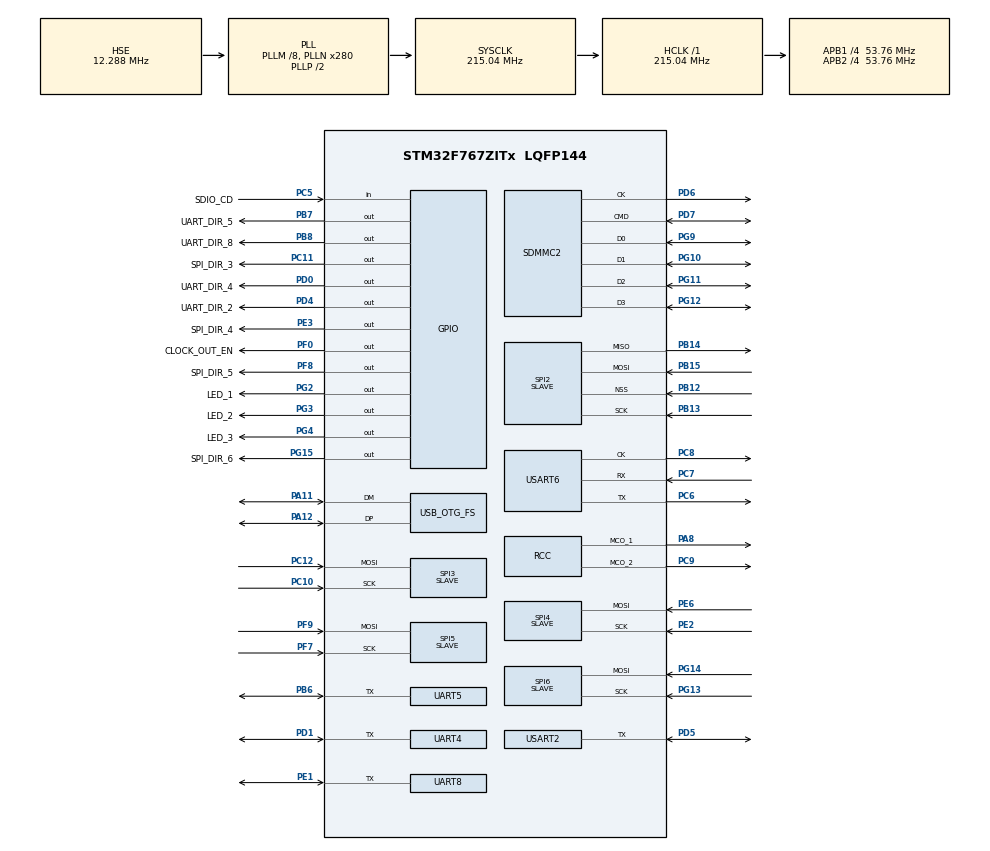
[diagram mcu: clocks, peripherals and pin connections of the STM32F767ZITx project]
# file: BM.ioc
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Dma.Request0=SPI3_RX
Dma.Request1=SPI4_RX
Dma.Request2=SPI5_RX
Dma.Request3=SPI6_RX
Dma.SPI3_RX.0.Direction=DMA_PERIPH_TO_MEMORY
Dma.SPI3_RX.0.FIFOMode=DMA_FIFOMODE_DISABLE
Dma.SPI3_RX.0.Instance=DMA1_Stream0
Dma.SPI3_RX.0.MemDataAlignment=DMA_MDATAALIGN_HALFWORD
Dma.SPI3_RX.0.MemInc=DMA_MINC_ENABLE
Dma.SPI3_RX.0.Mode=DMA_CIRCULAR
Dma.SPI3_RX.0.PeriphDataAlignment=DMA_PDATAALIGN_HALFWORD
Dma.SPI3_RX.0.PeriphInc=DMA_PINC_DISABLE
Dma.SPI3_RX.0.Priority=DMA_PRIORITY_MEDIUM
Dma.SPI4_RX.1.Direction=DMA_PERIPH_TO_MEMORY
Dma.SPI4_RX.1.FIFOMode=DMA_FIFOMODE_DISABLE
Dma.SPI4_RX.1.Instance=DMA2_Stream0
Dma.SPI4_RX.1.MemDataAlignment=DMA_MDATAALIGN_HALFWORD
Dma.SPI4_RX.1.MemInc=DMA_MINC_ENABLE
Dma.SPI4_RX.1.Mode=DMA_CIRCULAR
Dma.SPI4_RX.1.PeriphDataAlignment=DMA_PDATAALIGN_HALFWORD
Dma.SPI4_RX.1.PeriphInc=DMA_PINC_DISABLE
Dma.SPI4_RX.1.Priority=DMA_PRIORITY_MEDIUM
Dma.SPI5_RX.2.Direction=DMA_PERIPH_TO_MEMORY
Dma.SPI5_RX.2.FIFOMode=DMA_FIFOMODE_DISABLE
Dma.SPI5_RX.2.Instance=DMA2_Stream3
Dma.SPI5_RX.2.MemDataAlignment=DMA_MDATAALIGN_BYTE
Dma.SPI5_RX.2.MemInc=DMA_MINC_ENABLE
Dma.SPI5_RX.2.Mode=DMA_CIRCULAR
Dma.SPI5_RX.2.PeriphDataAlignment=DMA_PDATAALIGN_BYTE
Dma.SPI5_RX.2.PeriphInc=DMA_PINC_DISABLE
Dma.SPI5_RX.2.Priority=DMA_PRIORITY_MEDIUM
Dma.SPI6_RX.3.Direction=DMA_PERIPH_TO_MEMORY
Dma.SPI6_RX.3.FIFOMode=DMA_FIFOMODE_DISABLE
Dma.SPI6_RX.3.Instance=DMA2_Stream6
Dma.SPI6_RX.3.MemDataAlignment=DMA_MDATAALIGN_BYTE
Dma.SPI6_RX.3.MemInc=DMA_MINC_ENABLE
Dma.SPI6_RX.3.Mode=DMA_CIRCULAR
Dma.SPI6_RX.3.PeriphDataAlignment=DMA_PDATAALIGN_BYTE
Dma.SPI6_RX.3.PeriphInc=DMA_PINC_DISABLE
Dma.SPI6_RX.3.Priority=DMA_PRIORITY_MEDIUM
Mcu.Family=STM32F7
Mcu.Name=STM32F767ZITx
Mcu.Package=LQFP144
NVIC.DMA1_Stream0_IRQn=true\:0\:0\:false\:false\:true\:false
NVIC.DMA2_Stream0_IRQn=true\:0\:0\:false\:false\:true\:false
NVIC.DMA2_Stream3_IRQn=true\:0\:0\:false\:false\:true\:false
NVIC.DMA2_Stream6_IRQn=true\:0\:0\:false\:false\:true\:false
NVIC.OTG_FS_IRQn=true\:0\:0\:false\:false\:true\:false
NVIC.PriorityGroup=NVIC_PRIORITYGROUP_4
NVIC.TIM1_UP_TIM10_IRQn=true\:0\:0\:false\:false\:true\:true
PA11.Mode=Device_Only
PA11.Signal=USB_OTG_FS_DM
PA12.Mode=Device_Only
PA12.Signal=USB_OTG_FS_DP
PA8.Mode=Clock-out-1
PA8.Signal=RCC_MCO_1
PB12.Mode=NSS_Signal_Hard_Input
PB12.Signal=SPI2_NSS
PB13.Mode=Full_Duplex_Slave
PB13.Signal=SPI2_SCK
PB14.Mode=Full_Duplex_Slave
PB14.Signal=SPI2_MISO
PB15.Mode=Full_Duplex_Slave
PB15.Signal=SPI2_MOSI
PB6.Mode=Half_duplex(single_wire_mode)
PB6.Signal=UART5_TX
PB7.GPIO_Label=UART_DIR_5
PB7.GPIO_Speed=GPIO_SPEED_FREQ_VERY_HIGH
PB7.Signal=GPIO_Output
PB8.GPIO_Label=UART_DIR_8
PB8.GPIO_Speed=GPIO_SPEED_FREQ_VERY_HIGH
PB8.Signal=GPIO_Output
PC10.Mode=RX_Only_Simplex_Unidirect_Slave
PC10.Signal=SPI3_SCK
PC11.GPIO_Label=SPI_DIR_3
PC11.GPIO_Speed=GPIO_SPEED_FREQ_VERY_HIGH
PC11.Signal=GPIO_Output
PC12.Mode=RX_Only_Simplex_Unidirect_Slave
PC12.Signal=SPI3_MOSI
PC14/OSC32_IN.Mode=LSE-External-Oscillator
PC14/OSC32_IN.Signal=RCC_OSC32_IN
PC15/OSC32_OUT.Mode=LSE-External-Oscillator
PC15/OSC32_OUT.Signal=RCC_OSC32_OUT
PC5.GPIO_Label=SDIO_CD
PC5.Signal=GPIO_Input
PC6.Mode=Synchronous
PC6.Signal=USART6_TX
PC7.Mode=Synchronous
PC7.Signal=USART6_RX
PC8.Mode=Synchronous
PC8.Signal=USART6_CK
PC9.Mode=Clock-out-2
PC9.Signal=RCC_MCO_2
PD0.GPIO_Label=UART_DIR_4
PD0.GPIO_Speed=GPIO_SPEED_FREQ_VERY_HIGH
PD0.Signal=GPIO_Output
PD1.Mode=Half_duplex(single_wire_mode)
PD1.Signal=UART4_TX
PD4.GPIO_Label=UART_DIR_2
PD4.GPIO_Speed=GPIO_SPEED_FREQ_VERY_HIGH
PD4.Signal=GPIO_Output
PD5.Mode=Half_duplex(single_wire_mode)
PD5.Signal=USART2_TX
PD6.Mode=SD_4_bits_Wide_bus
PD6.Signal=SDMMC2_CK
PD7.Mode=SD_4_bits_Wide_bus
PD7.Signal=SDMMC2_CMD
PE1.Mode=Half_duplex(single_wire_mode)
PE1.Signal=UART8_TX
PE2.Mode=RX_Only_Simplex_Unidirect_Slave
PE2.Signal=SPI4_SCK
PE3.GPIO_Label=SPI_DIR_4
PE3.GPIO_Speed=GPIO_SPEED_FREQ_VERY_HIGH
PE3.Signal=GPIO_Output
PE6.Mode=RX_Only_Simplex_Unidirect_Slave
PE6.Signal=SPI4_MOSI
PF0.GPIO_Label=CLOCK_OUT_EN
PF0.GPIO_Speed=GPIO_SPEED_FREQ_VERY_HIGH
PF0.Signal=GPIO_Output
PF7.Mode=RX_Only_Simplex_Unidirect_Slave
PF7.Signal=SPI5_SCK
PF8.GPIO_Label=SPI_DIR_5
PF8.GPIO_Speed=GPIO_SPEED_FREQ_VERY_HIGH
PF8.Signal=GPIO_Output
PF9.Mode=RX_Only_Simplex_Unidirect_Slave
PF9.Signal=SPI5_MOSI
PG10.Mode=SD_4_bits_Wide_bus
PG10.Signal=SDMMC2_D1
PG11.Mode=SD_4_bits_Wide_bus
PG11.Signal=SDMMC2_D2
PG12.Mode=SD_4_bits_Wide_bus
PG12.Signal=SDMMC2_D3
PG13.Mode=RX_Only_Simplex_Unidirect_Slave
PG13.Signal=SPI6_SCK
PG14.Mode=RX_Only_Simplex_Unidirect_Slave
PG14.Signal=SPI6_MOSI
PG15.GPIO_Label=SPI_DIR_6
PG15.GPIO_Speed=GPIO_SPEED_FREQ_VERY_HIGH
PG15.Signal=GPIO_Output
PG2.GPIO_Label=LED_1
PG2.GPIO_Speed=GPIO_SPEED_FREQ_VERY_HIGH
PG2.Signal=GPIO_Output
PG3.GPIO_Label=LED_2
PG3.GPIO_Speed=GPIO_SPEED_FREQ_VERY_HIGH
PG3.Signal=GPIO_Output
PG4.GPIO_Label=LED_3
PG4.GPIO_Speed=GPIO_SPEED_FREQ_VERY_HIGH
PG4.Signal=GPIO_Output
PG9.Mode=SD_4_bits_Wide_bus
PG9.Signal=SDMMC2_D0
PH0/OSC_IN.Mode=HSE-External-Oscillator
PH0/OSC_IN.Signal=RCC_OSC_IN
PH1/OSC_OUT.Mode=HSE-External-Oscillator
PH1/OSC_OUT.Signal=RCC_OSC_OUT
ProjectManager.HeapSize=0x200
ProjectManager.StackSize=0x400
ProjectManager.TargetToolchain=MDK-ARM V5
RCC.AHBFreq_Value=215040000
RCC.APB1CLKDivider=RCC_HCLK_DIV4
RCC.APB1Freq_Value=53760000
RCC.APB1TimFreq_Value=107520000
RCC.APB2CLKDivider=RCC_HCLK_DIV4
RCC.APB2Freq_Value=53760000
RCC.APB2TimFreq_Value=107520000
RCC.CortexFreq_Value=215040000
RCC.HCLKFreq_Value=215040000
RCC.HSE_VALUE=12288000
RCC.HSI_VALUE=16000000
RCC.PLL48CLockSelection=RCC_CLK48SOURCE_PLLSAIP
RCC.PLLI2SN=224
RCC.PLLI2SR=7
RCC.PLLM=8
RCC.PLLN=280
RCC.PLLQ=8
RCC.PLLSAIN=250
RCC.PLLSAIP=RCC_PLLSAIP_DIV8
RCC.RCC_MCO1Source=RCC_MCO1SOURCE_HSE
RCC.RCC_MCO2Source=RCC_MCO2SOURCE_PLLI2SCLK
RCC.SDMMC2ClockSelection=RCC_SDMMC2CLKSOURCE_CLK48
RCC.SYSCLKFreq_VALUE=215040000
RCC.SYSCLKSource=RCC_SYSCLKSOURCE_PLLCLK
RCC.USBFreq_Value=48000000
RCC.VCOOutputFreq_Value=430080000
SPI2.Direction=SPI_DIRECTION_2LINES
SPI2.Mode=SPI_MODE_SLAVE
SPI2.VirtualNSS=VM_NSSHARD
SPI2.VirtualType=VM_SLAVE
SPI3.DataSize=SPI_DATASIZE_16BIT
SPI3.Direction=SPI_DIRECTION_2LINES_RXONLY
SPI3.Mode=SPI_MODE_SLAVE
SPI3.VirtualType=VM_SLAVE
SPI4.DataSize=SPI_DATASIZE_16BIT
SPI4.Direction=SPI_DIRECTION_2LINES_RXONLY
SPI4.Mode=SPI_MODE_SLAVE
SPI4.VirtualType=VM_SLAVE
SPI5.Direction=SPI_DIRECTION_2LINES_RXONLY
SPI5.Mode=SPI_MODE_SLAVE
SPI5.VirtualType=VM_SLAVE
SPI6.Direction=SPI_DIRECTION_2LINES_RXONLY
SPI6.Mode=SPI_MODE_SLAVE
SPI6.VirtualType=VM_SLAVE
TIM1.Period=10000
TIM1.Prescaler=10700
USART2.VirtualMode-Half_duplex(single_wire_mode)=VM_ASYNC
USART6.VirtualMode-Synchronous=VM_SYNC
USB_DEVICE.CLASS_NAME_FS=CDC
USB_DEVICE.USBD_LPM_ENABLED-CDC_FS=0
USB_DEVICE.USBD_SUPPORT_USER_STRING-CDC_FS=1
USB_DEVICE.VirtualMode-CDC_FS=Cdc
USB_DEVICE.VirtualModeFS=Cdc_FS
USB_OTG_FS.VirtualMode=Device_Only
USB_OTG_FS.lpm_enable=DISABLE
VP_FATFS_VS_SDIO.Mode=SDIO
VP_TIM1_VS_ClockSourceINT.Mode=Internal
VP_USB_DEVICE_VS_USB_DEVICE_CDC_FS.Mode=CDC_FS
board=BM

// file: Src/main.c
/**
  ******************************************************************************
  * @file           : main.c
  * @brief          : Main program body
  ******************************************************************************
  * This notice applies to any and all portions of this file
  * that are not between comment pairs USER CODE BEGIN and
  * USER CODE END. Other portions of this file, whether
  * inserted by the user or by software development tools
  * are owned by their respective copyright owners.
  *
  * Copyright (c) 2018 STMicroelectronics International N.V.
  * All rights reserved.
  *
  * Redistribution and use in source and binary forms, with or without
  * modification, are permitted, provided that the following conditions are met:
  *
  * 1. Redistribution of source code must retain the above copyright notice,
  *    this list of conditions and the following disclaimer.
  * 2. Redistributions in binary form must reproduce the above copyright notice,
  *    this list of conditions and the following disclaimer in the documentation
  *    and/or other materials provided with the distribution.
  * 3. Neither the name of STMicroelectronics nor the names of other
  *    contributors to this software may be used to endorse or promote products
  *    derived from this software without specific written permission.
  * 4. This software, including modifications and/or derivative works of this
  *    software, must execute solely and exclusively on microcontroller or
  *    microprocessor devices manufactured by or for STMicroelectronics.
  * 5. Redistribution and use of this software other than as permitted under
  *    this license is void and will automatically terminate your rights under
  *    this license.
  *
  * THIS SOFTWARE IS PROVIDED BY STMICROELECTRONICS AND CONTRIBUTORS "AS IS"
  * AND ANY EXPRESS, IMPLIED OR STATUTORY WARRANTIES, INCLUDING, BUT NOT
  * LIMITED TO, THE IMPLIED WARRANTIES OF MERCHANTABILITY, FITNESS FOR A
  * PARTICULAR PURPOSE AND NON-INFRINGEMENT OF THIRD PARTY INTELLECTUAL PROPERTY
  * RIGHTS ARE DISCLAIMED TO THE FULLEST EXTENT PERMITTED BY LAW. IN NO EVENT
  * SHALL STMICROELECTRONICS OR CONTRIBUTORS BE LIABLE FOR ANY DIRECT, INDIRECT,
  * INCIDENTAL, SPECIAL, EXEMPLARY, OR CONSEQUENTIAL DAMAGES (INCLUDING, BUT NOT
  * LIMITED TO, PROCUREMENT OF SUBSTITUTE GOODS OR SERVICES; LOSS OF USE, DATA,
  * OR PROFITS; OR BUSINESS INTERRUPTION) HOWEVER CAUSED AND ON ANY THEORY OF
  * LIABILITY, WHETHER IN CONTRACT, STRICT LIABILITY, OR TORT (INCLUDING
  * NEGLIGENCE OR OTHERWISE) ARISING IN ANY WAY OUT OF THE USE OF THIS SOFTWARE,
  * EVEN IF ADVISED OF THE POSSIBILITY OF SUCH DAMAGE.
  *
  ******************************************************************************
  */
#include "main.h"
#include "stm32f7xx_hal.h"
#include "fatfs.h"
#include "usb_device.h"

SD_HandleTypeDef hsd2;

SPI_HandleTypeDef hspi2;
SPI_HandleTypeDef hspi3;
SPI_HandleTypeDef hspi4;
SPI_HandleTypeDef hspi5;
SPI_HandleTypeDef hspi6;
DMA_HandleTypeDef hdma_spi3_rx;
DMA_HandleTypeDef hdma_spi4_rx;
DMA_HandleTypeDef hdma_spi5_rx;
DMA_HandleTypeDef hdma_spi6_rx;

TIM_HandleTypeDef htim1;

UART_HandleTypeDef huart4;
UART_HandleTypeDef huart5;
UART_HandleTypeDef huart8;
UART_HandleTypeDef huart2;
USART_HandleTypeDef husart6;

/* USER CODE BEGIN PV */
/* Private variables ---------------------------------------------------------*/

/* USER CODE END PV */

void SystemClock_Config(void);
static void MX_GPIO_Init(void);
static void MX_DMA_Init(void);
static void MX_TIM1_Init(void);
static void MX_SPI2_Init(void);
static void MX_USART6_Init(void);
static void MX_UART8_Init(void);
static void MX_UART5_Init(void);
static void MX_UART4_Init(void);
static void MX_USART2_UART_Init(void);
static void MX_SPI3_Init(void);
static void MX_SPI4_Init(void);
static void MX_SPI5_Init(void);
static void MX_SPI6_Init(void);
static void MX_SDMMC2_SD_Init(void);

/* USER CODE BEGIN PFP */
/* Private function prototypes -----------------------------------------------*/

/* USER CODE END PFP */

int main(void)
{

  /* MCU Configuration----------------------------------------------------------*/

  /* Reset of all peripherals, Initializes the Flash interface and the Systick. */
  HAL_Init();

  /* Configure the system clock */
  SystemClock_Config();

  /* Initialize all configured peripherals */
  MX_GPIO_Init();
  MX_DMA_Init();
  MX_TIM1_Init();
  MX_SPI2_Init();
  MX_USART6_Init();
  MX_UART8_Init();
  MX_UART5_Init();
  MX_UART4_Init();
  MX_USART2_UART_Init();
  MX_SPI3_Init();
  MX_SPI4_Init();
  MX_SPI5_Init();
  MX_SPI6_Init();
  MX_SDMMC2_SD_Init();
  MX_FATFS_Init();
  MX_USB_DEVICE_Init();
  /* USER CODE BEGIN 2 */

  HAL_TIM_Base_Start_IT(&htim1);

  /* USER CODE END 2 */

  /* Infinite loop */
  while (1)
  {

  }

}

void SystemClock_Config(void)
{

  RCC_OscInitTypeDef RCC_OscInitStruct;
  RCC_ClkInitTypeDef RCC_ClkInitStruct;
  RCC_PeriphCLKInitTypeDef PeriphClkInitStruct;

    /**Configure the main internal regulator output voltage
    */
  __HAL_RCC_PWR_CLK_ENABLE();

  __HAL_PWR_VOLTAGESCALING_CONFIG(PWR_REGULATOR_VOLTAGE_SCALE1);

    /**Initializes the CPU, AHB and APB busses clocks
    */
  RCC_OscInitStruct.OscillatorType = RCC_OSCILLATORTYPE_HSE;
  RCC_OscInitStruct.HSEState = RCC_HSE_ON;
  RCC_OscInitStruct.PLL.PLLState = RCC_PLL_ON;
  RCC_OscInitStruct.PLL.PLLSource = RCC_PLLSOURCE_HSE;
  RCC_OscInitStruct.PLL.PLLM = 8;
  RCC_OscInitStruct.PLL.PLLN = 280;
  RCC_OscInitStruct.PLL.PLLP = RCC_PLLP_DIV2;
  RCC_OscInitStruct.PLL.PLLQ = 8;
  if (HAL_RCC_OscConfig(&RCC_OscInitStruct) != HAL_OK)
  {
    _Error_Handler(__FILE__, __LINE__);
  }

    /**Activate the Over-Drive mode
    */
  if (HAL_PWREx_EnableOverDrive() != HAL_OK)
  {
    _Error_Handler(__FILE__, __LINE__);
  }

    /**Initializes the CPU, AHB and APB busses clocks
    */
  RCC_ClkInitStruct.ClockType = RCC_CLOCKTYPE_HCLK|RCC_CLOCKTYPE_SYSCLK
                              |RCC_CLOCKTYPE_PCLK1|RCC_CLOCKTYPE_PCLK2;
  RCC_ClkInitStruct.SYSCLKSource = RCC_SYSCLKSOURCE_PLLCLK;
  RCC_ClkInitStruct.AHBCLKDivider = RCC_SYSCLK_DIV1;
  RCC_ClkInitStruct.APB1CLKDivider = RCC_HCLK_DIV4;
  RCC_ClkInitStruct.APB2CLKDivider = RCC_HCLK_DIV4;

  if (HAL_RCC_ClockConfig(&RCC_ClkInitStruct, FLASH_LATENCY_7) != HAL_OK)
  {
    _Error_Handler(__FILE__, __LINE__);
  }

  PeriphClkInitStruct.PeriphClockSelection = RCC_PERIPHCLK_PLLI2S|RCC_PERIPHCLK_USART2
                              |RCC_PERIPHCLK_USART6|RCC_PERIPHCLK_UART4
                              |RCC_PERIPHCLK_UART5|RCC_PERIPHCLK_UART8
                              |RCC_PERIPHCLK_SDMMC2|RCC_PERIPHCLK_CLK48;
  PeriphClkInitStruct.PLLI2S.PLLI2SN = 224;
  PeriphClkInitStruct.PLLI2S.PLLI2SP = RCC_PLLP_DIV2;
  PeriphClkInitStruct.PLLI2S.PLLI2SR = 7;
  PeriphClkInitStruct.PLLI2S.PLLI2SQ = 2;
  PeriphClkInitStruct.PLLSAI.PLLSAIN = 250;
  PeriphClkInitStruct.PLLSAI.PLLSAIR = 2;
  PeriphClkInitStruct.PLLSAI.PLLSAIQ = 2;
  PeriphClkInitStruct.PLLSAI.PLLSAIP = RCC_PLLSAIP_DIV8;
  PeriphClkInitStruct.PLLI2SDivQ = 1;
  PeriphClkInitStruct.PLLSAIDivQ = 1;
  PeriphClkInitStruct.PLLSAIDivR = RCC_PLLSAIDIVR_2;
  PeriphClkInitStruct.Usart2ClockSelection = RCC_USART2CLKSOURCE_PCLK1;
  PeriphClkInitStruct.Uart4ClockSelection = RCC_UART4CLKSOURCE_PCLK1;
  PeriphClkInitStruct.Uart5ClockSelection = RCC_UART5CLKSOURCE_PCLK1;
  PeriphClkInitStruct.Usart6ClockSelection = RCC_USART6CLKSOURCE_PCLK2;
  PeriphClkInitStruct.Uart8ClockSelection = RCC_UART8CLKSOURCE_PCLK1;
  PeriphClkInitStruct.Clk48ClockSelection = RCC_CLK48SOURCE_PLLSAIP;
  PeriphClkInitStruct.Sdmmc2ClockSelection = RCC_SDMMC2CLKSOURCE_CLK48;
  if (HAL_RCCEx_PeriphCLKConfig(&PeriphClkInitStruct) != HAL_OK)
  {
    _Error_Handler(__FILE__, __LINE__);
  }

  HAL_RCC_MCOConfig(RCC_MCO1, RCC_MCO1SOURCE_HSE, RCC_MCODIV_1);

  HAL_RCC_MCOConfig(RCC_MCO2, RCC_MCO2SOURCE_PLLI2SCLK, RCC_MCODIV_1);

    /**Configure the Systick interrupt time
    */
  HAL_SYSTICK_Config(HAL_RCC_GetHCLKFreq()/1000);

    /**Configure the Systick
    */
  HAL_SYSTICK_CLKSourceConfig(SYSTICK_CLKSOURCE_HCLK);

  /* SysTick_IRQn interrupt configuration */
  HAL_NVIC_SetPriority(SysTick_IRQn, 0, 0);
}

/* SDMMC2 init function */
static void MX_SDMMC2_SD_Init(void)
{

  hsd2.Instance = SDMMC2;
  hsd2.Init.ClockEdge = SDMMC_CLOCK_EDGE_RISING;
  hsd2.Init.ClockBypass = SDMMC_CLOCK_BYPASS_DISABLE;
  hsd2.Init.ClockPowerSave = SDMMC_CLOCK_POWER_SAVE_DISABLE;
  hsd2.Init.BusWide = SDMMC_BUS_WIDE_1B;
  hsd2.Init.HardwareFlowControl = SDMMC_HARDWARE_FLOW_CONTROL_DISABLE;
  hsd2.Init.ClockDiv = 0;

}

/* SPI2 init function */
static void MX_SPI2_Init(void)
{

  /* SPI2 parameter configuration*/
  hspi2.Instance = SPI2;
  hspi2.Init.Mode = SPI_MODE_SLAVE;
  hspi2.Init.Direction = SPI_DIRECTION_2LINES;
  hspi2.Init.DataSize = SPI_DATASIZE_4BIT;
  hspi2.Init.CLKPolarity = SPI_POLARITY_LOW;
  hspi2.Init.CLKPhase = SPI_PHASE_1EDGE;
  hspi2.Init.NSS = SPI_NSS_HARD_INPUT;
  hspi2.Init.FirstBit = SPI_FIRSTBIT_MSB;
  hspi2.Init.TIMode = SPI_TIMODE_DISABLE;
  hspi2.Init.CRCCalculation = SPI_CRCCALCULATION_DISABLE;
  hspi2.Init.CRCPolynomial = 7;
  hspi2.Init.CRCLength = SPI_CRC_LENGTH_DATASIZE;
  hspi2.Init.NSSPMode = SPI_NSS_PULSE_DISABLE;
  if (HAL_SPI_Init(&hspi2) != HAL_OK)
  {
    _Error_Handler(__FILE__, __LINE__);
  }

}

/* SPI3 init function */
static void MX_SPI3_Init(void)
{

  /* SPI3 parameter configuration*/
  hspi3.Instance = SPI3;
  hspi3.Init.Mode = SPI_MODE_SLAVE;
  hspi3.Init.Direction = SPI_DIRECTION_2LINES_RXONLY;
  hspi3.Init.DataSize = SPI_DATASIZE_16BIT;
  hspi3.Init.CLKPolarity = SPI_POLARITY_LOW;
  hspi3.Init.CLKPhase = SPI_PHASE_1EDGE;
  hspi3.Init.NSS = SPI_NSS_SOFT;
  hspi3.Init.FirstBit = SPI_FIRSTBIT_MSB;
  hspi3.Init.TIMode = SPI_TIMODE_DISABLE;
  hspi3.Init.CRCCalculation = SPI_CRCCALCULATION_DISABLE;
  hspi3.Init.CRCPolynomial = 7;
  hspi3.Init.CRCLength = SPI_CRC_LENGTH_DATASIZE;
  hspi3.Init.NSSPMode = SPI_NSS_PULSE_DISABLE;
  if (HAL_SPI_Init(&hspi3) != HAL_OK)
  {
    _Error_Handler(__FILE__, __LINE__);
  }

}

/* SPI4 init function */
static void MX_SPI4_Init(void)
{

  /* SPI4 parameter configuration*/
  hspi4.Instance = SPI4;
  hspi4.Init.Mode = SPI_MODE_SLAVE;
  hspi4.Init.Direction = SPI_DIRECTION_2LINES_RXONLY;
  hspi4.Init.DataSize = SPI_DATASIZE_16BIT;
  hspi4.Init.CLKPolarity = SPI_POLARITY_LOW;
  hspi4.Init.CLKPhase = SPI_PHASE_1EDGE;
  hspi4.Init.NSS = SPI_NSS_SOFT;
  hspi4.Init.FirstBit = SPI_FIRSTBIT_MSB;
  hspi4.Init.TIMode = SPI_TIMODE_DISABLE;
  hspi4.Init.CRCCalculation = SPI_CRCCALCULATION_DISABLE;
  hspi4.Init.CRCPolynomial = 7;
  hspi4.Init.CRCLength = SPI_CRC_LENGTH_DATASIZE;
  hspi4.Init.NSSPMode = SPI_NSS_PULSE_DISABLE;
  if (HAL_SPI_Init(&hspi4) != HAL_OK)
  {
    _Error_Handler(__FILE__, __LINE__);
  }

}

/* SPI5 init function */
static void MX_SPI5_Init(void)
{

  /* SPI5 parameter configuration*/
  hspi5.Instance = SPI5;
  hspi5.Init.Mode = SPI_MODE_SLAVE;
  hspi5.Init.Direction = SPI_DIRECTION_2LINES_RXONLY;
  hspi5.Init.DataSize = SPI_DATASIZE_4BIT;
  hspi5.Init.CLKPolarity = SPI_POLARITY_LOW;
  hspi5.Init.CLKPhase = SPI_PHASE_1EDGE;
  hspi5.Init.NSS = SPI_NSS_SOFT;
  hspi5.Init.FirstBit = SPI_FIRSTBIT_MSB;
  hspi5.Init.TIMode = SPI_TIMODE_DISABLE;
  hspi5.Init.CRCCalculation = SPI_CRCCALCULATION_DISABLE;
  hspi5.Init.CRCPolynomial = 7;
  hspi5.Init.CRCLength = SPI_CRC_LENGTH_DATASIZE;
  hspi5.Init.NSSPMode = SPI_NSS_PULSE_DISABLE;
  if (HAL_SPI_Init(&hspi5) != HAL_OK)
  {
    _Error_Handler(__FILE__, __LINE__);
  }

}

/* SPI6 init function */
static void MX_SPI6_Init(void)
{

  /* SPI6 parameter configuration*/
  hspi6.Instance = SPI6;
  hspi6.Init.Mode = SPI_MODE_SLAVE;
  hspi6.Init.Direction = SPI_DIRECTION_2LINES_RXONLY;
  hspi6.Init.DataSize = SPI_DATASIZE_4BIT;
  hspi6.Init.CLKPolarity = SPI_POLARITY_LOW;
  hspi6.Init.CLKPhase = SPI_PHASE_1EDGE;
  hspi6.Init.NSS = SPI_NSS_SOFT;
  hspi6.Init.FirstBit = SPI_FIRSTBIT_MSB;
  hspi6.Init.TIMode = SPI_TIMODE_DISABLE;
  hspi6.Init.CRCCalculation = SPI_CRCCALCULATION_DISABLE;
  hspi6.Init.CRCPolynomial = 7;
  hspi6.Init.CRCLength = SPI_CRC_LENGTH_DATASIZE;
  hspi6.Init.NSSPMode = SPI_NSS_PULSE_DISABLE;
  if (HAL_SPI_Init(&hspi6) != HAL_OK)
  {
    _Error_Handler(__FILE__, __LINE__);
  }

}

/* TIM1 init function */
static void MX_TIM1_Init(void)
{

  TIM_ClockConfigTypeDef sClockSourceConfig;
  TIM_MasterConfigTypeDef sMasterConfig;

  htim1.Instance = TIM1;
  htim1.Init.Prescaler = 10700;
  htim1.Init.CounterMode = TIM_COUNTERMODE_UP;
  htim1.Init.Period = 10000;
  htim1.Init.ClockDivision = TIM_CLOCKDIVISION_DIV1;
  htim1.Init.RepetitionCounter = 0;
  htim1.Init.AutoReloadPreload = TIM_AUTORELOAD_PRELOAD_DISABLE;
  if (HAL_TIM_Base_Init(&htim1) != HAL_OK)
  {
    _Error_Handler(__FILE__, __LINE__);
  }

  sClockSourceConfig.ClockSource = TIM_CLOCKSOURCE_INTERNAL;
  if (HAL_TIM_ConfigClockSource(&htim1, &sClockSourceConfig) != HAL_OK)
  {
    _Error_Handler(__FILE__, __LINE__);
  }

  sMasterConfig.MasterOutputTrigger = TIM_TRGO_RESET;
  sMasterConfig.MasterOutputTrigger2 = TIM_TRGO2_RESET;
  sMasterConfig.MasterSlaveMode = TIM_MASTERSLAVEMODE_DISABLE;
  if (HAL_TIMEx_MasterConfigSynchronization(&htim1, &sMasterConfig) != HAL_OK)
  {
    _Error_Handler(__FILE__, __LINE__);
  }

}

/* UART4 init function */
static void MX_UART4_Init(void)
{

  huart4.Instance = UART4;
  huart4.Init.BaudRate = 115200;
  huart4.Init.WordLength = UART_WORDLENGTH_8B;
  huart4.Init.StopBits = UART_STOPBITS_1;
  huart4.Init.Parity = UART_PARITY_NONE;
  huart4.Init.Mode = UART_MODE_TX_RX;
  huart4.Init.HwFlowCtl = UART_HWCONTROL_NONE;
  huart4.Init.OverSampling = UART_OVERSAMPLING_16;
  huart4.Init.OneBitSampling = UART_ONE_BIT_SAMPLE_DISABLE;
  huart4.AdvancedInit.AdvFeatureInit = UART_ADVFEATURE_NO_INIT;
  if (HAL_HalfDuplex_Init(&huart4) != HAL_OK)
  {
    _Error_Handler(__FILE__, __LINE__);
  }

}

/* UART5 init function */
static void MX_UART5_Init(void)
{

  huart5.Instance = UART5;
  huart5.Init.BaudRate = 115200;
  huart5.Init.WordLength = UART_WORDLENGTH_8B;
  huart5.Init.StopBits = UART_STOPBITS_1;
  huart5.Init.Parity = UART_PARITY_NONE;
  huart5.Init.Mode = UART_MODE_TX_RX;
  huart5.Init.HwFlowCtl = UART_HWCONTROL_NONE;
  huart5.Init.OverSampling = UART_OVERSAMPLING_16;
  huart5.Init.OneBitSampling = UART_ONE_BIT_SAMPLE_DISABLE;
  huart5.AdvancedInit.AdvFeatureInit = UART_ADVFEATURE_NO_INIT;
  if (HAL_HalfDuplex_Init(&huart5) != HAL_OK)
  {
    _Error_Handler(__FILE__, __LINE__);
  }

}

/* UART8 init function */
static void MX_UART8_Init(void)
{

  huart8.Instance = UART8;
  huart8.Init.BaudRate = 115200;
  huart8.Init.WordLength = UART_WORDLENGTH_8B;
  huart8.Init.StopBits = UART_STOPBITS_1;
  huart8.Init.Parity = UART_PARITY_NONE;
  huart8.Init.Mode = UART_MODE_TX_RX;
  huart8.Init.HwFlowCtl = UART_HWCONTROL_NONE;
  huart8.Init.OverSampling = UART_OVERSAMPLING_16;
  huart8.Init.OneBitSampling = UART_ONE_BIT_SAMPLE_DISABLE;
  huart8.AdvancedInit.AdvFeatureInit = UART_ADVFEATURE_NO_INIT;
  if (HAL_HalfDuplex_Init(&huart8) != HAL_OK)
  {
    _Error_Handler(__FILE__, __LINE__);
  }

}

/* USART2 init function */
static void MX_USART2_UART_Init(void)
{

  huart2.Instance = USART2;
  huart2.Init.BaudRate = 115200;
  huart2.Init.WordLength = UART_WORDLENGTH_8B;
  huart2.Init.StopBits = UART_STOPBITS_1;
  huart2.Init.Parity = UART_PARITY_NONE;
  huart2.Init.Mode = UART_MODE_TX_RX;
  huart2.Init.HwFlowCtl = UART_HWCONTROL_NONE;
  huart2.Init.OverSampling = UART_OVERSAMPLING_16;
  huart2.Init.OneBitSampling = UART_ONE_BIT_SAMPLE_DISABLE;
  huart2.AdvancedInit.AdvFeatureInit = UART_ADVFEATURE_NO_INIT;
  if (HAL_HalfDuplex_Init(&huart2) != HAL_OK)
  {
    _Error_Handler(__FILE__, __LINE__);
  }

}

/* USART6 init function */
static void MX_USART6_Init(void)
{

  husart6.Instance = USART6;
  husart6.Init.BaudRate = 115200;
  husart6.Init.WordLength = USART_WORDLENGTH_8B;
  husart6.Init.StopBits = USART_STOPBITS_1;
  husart6.Init.Parity = USART_PARITY_NONE;
  husart6.Init.Mode = USART_MODE_TX_RX;
  husart6.Init.CLKPolarity = USART_POLARITY_LOW;
  husart6.Init.CLKPhase = USART_PHASE_1EDGE;
  husart6.Init.CLKLastBit = USART_LASTBIT_DISABLE;
  if (HAL_USART_Init(&husart6) != HAL_OK)
  {
    _Error_Handler(__FILE__, __LINE__);
  }

}

static void MX_DMA_Init(void)
{
  /* DMA controller clock enable */
  __HAL_RCC_DMA1_CLK_ENABLE();
  __HAL_RCC_DMA2_CLK_ENABLE();

  /* DMA interrupt init */
  /* DMA1_Stream0_IRQn interrupt configuration */
  HAL_NVIC_SetPriority(DMA1_Stream0_IRQn, 0, 0);
  HAL_NVIC_EnableIRQ(DMA1_Stream0_IRQn);
  /* DMA2_Stream0_IRQn interrupt configuration */
  HAL_NVIC_SetPriority(DMA2_Stream0_IRQn, 0, 0);
  HAL_NVIC_EnableIRQ(DMA2_Stream0_IRQn);
  /* DMA2_Stream3_IRQn interrupt configuration */
  HAL_NVIC_SetPriority(DMA2_Stream3_IRQn, 0, 0);
  HAL_NVIC_EnableIRQ(DMA2_Stream3_IRQn);
  /* DMA2_Stream6_IRQn interrupt configuration */
  HAL_NVIC_SetPriority(DMA2_Stream6_IRQn, 0, 0);
  HAL_NVIC_EnableIRQ(DMA2_Stream6_IRQn);

}

/** Configure pins as
        * Analog
        * Input
        * Output
        * EVENT_OUT
        * EXTI
     PC9   ------> RCC_MCO_2
     PA8   ------> RCC_MCO_1
*/
static void MX_GPIO_Init(void)
{

  GPIO_InitTypeDef GPIO_InitStruct;

  /* GPIO Ports Clock Enable */
  __HAL_RCC_GPIOE_CLK_ENABLE();
  __HAL_RCC_GPIOC_CLK_ENABLE();
  __HAL_RCC_GPIOF_CLK_ENABLE();
  __HAL_RCC_GPIOH_CLK_ENABLE();
  __HAL_RCC_GPIOB_CLK_ENABLE();
  __HAL_RCC_GPIOG_CLK_ENABLE();
  __HAL_RCC_GPIOA_CLK_ENABLE();
  __HAL_RCC_GPIOD_CLK_ENABLE();

  /*Configure GPIO pin Output Level */
  HAL_GPIO_WritePin(SPI_DIR_4_GPIO_Port, SPI_DIR_4_Pin, GPIO_PIN_RESET);

  /*Configure GPIO pin Output Level */
  HAL_GPIO_WritePin(GPIOF, CLOCK_OUT_EN_Pin|SPI_DIR_5_Pin, GPIO_PIN_RESET);

  /*Configure GPIO pin Output Level */
  HAL_GPIO_WritePin(GPIOG, LED_1_Pin|LED_2_Pin|LED_3_Pin|SPI_DIR_6_Pin, GPIO_PIN_RESET);

  /*Configure GPIO pin Output Level */
  HAL_GPIO_WritePin(SPI_DIR_3_GPIO_Port, SPI_DIR_3_Pin, GPIO_PIN_RESET);

  /*Configure GPIO pin Output Level */
  HAL_GPIO_WritePin(GPIOD, UART_DIR_4_Pin|UART_DIR_2_Pin, GPIO_PIN_RESET);

  /*Configure GPIO pin Output Level */
  HAL_GPIO_WritePin(GPIOB, UART_DIR_5_Pin|UART_DIR_8_Pin, GPIO_PIN_RESET);

  /*Configure GPIO pin : SPI_DIR_4_Pin */
  GPIO_InitStruct.Pin = SPI_DIR_4_Pin;
  GPIO_InitStruct.Mode = GPIO_MODE_OUTPUT_PP;
  GPIO_InitStruct.Pull = GPIO_NOPULL;
  GPIO_InitStruct.Speed = GPIO_SPEED_FREQ_VERY_HIGH;
  HAL_GPIO_Init(SPI_DIR_4_GPIO_Port, &GPIO_InitStruct);

  /*Configure GPIO pins : CLOCK_OUT_EN_Pin SPI_DIR_5_Pin */
  GPIO_InitStruct.Pin = CLOCK_OUT_EN_Pin|SPI_DIR_5_Pin;
  GPIO_InitStruct.Mode = GPIO_MODE_OUTPUT_PP;
  GPIO_InitStruct.Pull = GPIO_NOPULL;
  GPIO_InitStruct.Speed = GPIO_SPEED_FREQ_VERY_HIGH;
  HAL_GPIO_Init(GPIOF, &GPIO_InitStruct);

  /*Configure GPIO pin : SDIO_CD_Pin */
  GPIO_InitStruct.Pin = SDIO_CD_Pin;
  GPIO_InitStruct.Mode = GPIO_MODE_INPUT;
  GPIO_InitStruct.Pull = GPIO_NOPULL;
  HAL_GPIO_Init(SDIO_CD_GPIO_Port, &GPIO_InitStruct);

  /*Configure GPIO pins : LED_1_Pin LED_2_Pin LED_3_Pin SPI_DIR_6_Pin */
  GPIO_InitStruct.Pin = LED_1_Pin|LED_2_Pin|LED_3_Pin|SPI_DIR_6_Pin;
  GPIO_InitStruct.Mode = GPIO_MODE_OUTPUT_PP;
  GPIO_InitStruct.Pull = GPIO_NOPULL;
  GPIO_InitStruct.Speed = GPIO_SPEED_FREQ_VERY_HIGH;
  HAL_GPIO_Init(GPIOG, &GPIO_InitStruct);

  /*Configure GPIO pin : PC9 */
  GPIO_InitStruct.Pin = GPIO_PIN_9;
  GPIO_InitStruct.Mode = GPIO_MODE_AF_PP;
  GPIO_InitStruct.Pull = GPIO_NOPULL;
  GPIO_InitStruct.Speed = GPIO_SPEED_FREQ_LOW;
  GPIO_InitStruct.Alternate = GPIO_AF0_MCO;
  HAL_GPIO_Init(GPIOC, &GPIO_InitStruct);

  /*Configure GPIO pin : PA8 */
  GPIO_InitStruct.Pin = GPIO_PIN_8;
  GPIO_InitStruct.Mode = GPIO_MODE_AF_PP;
  GPIO_InitStruct.Pull = GPIO_NOPULL;
  GPIO_InitStruct.Speed = GPIO_SPEED_FREQ_LOW;
  GPIO_InitStruct.Alternate = GPIO_AF0_MCO;
  HAL_GPIO_Init(GPIOA, &GPIO_InitStruct);

  /*Configure GPIO pin : SPI_DIR_3_Pin */
  GPIO_InitStruct.Pin = SPI_DIR_3_Pin;
  GPIO_InitStruct.Mode = GPIO_MODE_OUTPUT_PP;
  GPIO_InitStruct.Pull = GPIO_NOPULL;
  GPIO_InitStruct.Speed = GPIO_SPEED_FREQ_VERY_HIGH;
  HAL_GPIO_Init(SPI_DIR_3_GPIO_Port, &GPIO_InitStruct);

  /*Configure GPIO pins : UART_DIR_4_Pin UART_DIR_2_Pin */
  GPIO_InitStruct.Pin = UART_DIR_4_Pin|UART_DIR_2_Pin;
  GPIO_InitStruct.Mode = GPIO_MODE_OUTPUT_PP;
  GPIO_InitStruct.Pull = GPIO_NOPULL;
  GPIO_InitStruct.Speed = GPIO_SPEED_FREQ_VERY_HIGH;
  HAL_GPIO_Init(GPIOD, &GPIO_InitStruct);

  /*Configure GPIO pins : UART_DIR_5_Pin UART_DIR_8_Pin */
  GPIO_InitStruct.Pin = UART_DIR_5_Pin|UART_DIR_8_Pin;
  GPIO_InitStruct.Mode = GPIO_MODE_OUTPUT_PP;
  GPIO_InitStruct.Pull = GPIO_NOPULL;
  GPIO_InitStruct.Speed = GPIO_SPEED_FREQ_VERY_HIGH;
  HAL_GPIO_Init(GPIOB, &GPIO_InitStruct);

}

void _Error_Handler(char *file, int line)
{
  while(1)
  {
  }
}

/************************ (C) COPYRIGHT STMicroelectronics *****END OF FILE****/
